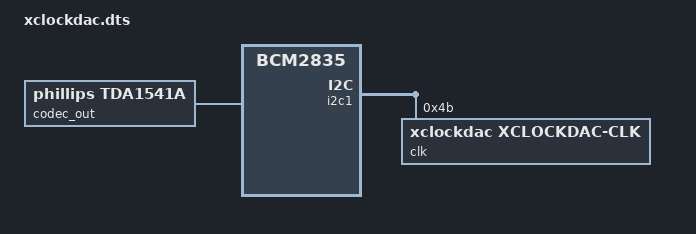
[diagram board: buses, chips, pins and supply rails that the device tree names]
// Definitions for XclockDAC tda1541a
/dts-v1/;
/plugin/;

/ {
	compatible = "brcm,bcm2835";

	fragment@0 {
		target = <&i2s_clk_consumer>;
		__overlay__ {
			status = "okay";
		};
	};

	fragment@1 {
		target = <&i2c1>;
		__overlay__ {
			#address-cells = <1>;
			#size-cells = <0>;
			status = "okay";

			clk: clk@4B {
				compatible = "xclockdac,xclockdac-clk";
				#clock-cells = <0>;
				reg = <0x4B>;
				status = "okay";
			};
		};
	};

	fragment@2 {
		target-path = "/";
		__overlay__ {
			codec_out: tda1541a-codec {
				compatible = "phillips,tda1541a";
				#sound-dai-cells = <0>;
				#clock-cells = <0>;
				status = "okay";
			};
		};
	};

	fragment@3 {
		target = <&sound>;
		__overlay__ {
			compatible = "xclockdac,xclockdac";
			i2s-controller = <&i2s_clk_consumer>;
			clocks = <&clk 0>;
			status = "okay";
		};
	};
};
